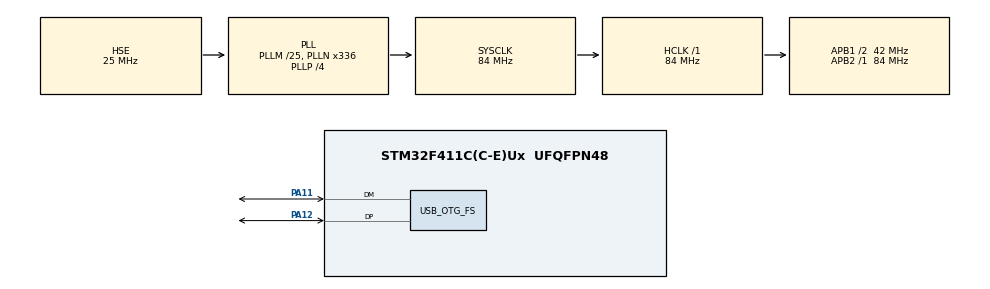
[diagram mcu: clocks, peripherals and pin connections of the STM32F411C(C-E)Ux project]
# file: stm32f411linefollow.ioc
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Mcu.Family=STM32F4
Mcu.Name=STM32F411C(C-E)Ux
Mcu.Package=UFQFPN48
NVIC.PriorityGroup=NVIC_PRIORITYGROUP_4
PA11.Mode=Device_Only
PA11.Signal=USB_OTG_FS_DM
PA12.Mode=Device_Only
PA12.Signal=USB_OTG_FS_DP
PH0\ -\ OSC_IN.Mode=HSE-External-Oscillator
PH0\ -\ OSC_IN.Signal=RCC_OSC_IN
PH1\ -\ OSC_OUT.Mode=HSE-External-Oscillator
PH1\ -\ OSC_OUT.Signal=RCC_OSC_OUT
ProjectManager.HeapSize=0x200
ProjectManager.StackSize=0x400
ProjectManager.TargetToolchain=STM32CubeIDE
RCC.48MHZClocksFreq_Value=48000000
RCC.AHBFreq_Value=84000000
RCC.APB1CLKDivider=RCC_HCLK_DIV2
RCC.APB1Freq_Value=42000000
RCC.APB1TimFreq_Value=84000000
RCC.APB2Freq_Value=84000000
RCC.APB2TimFreq_Value=84000000
RCC.CortexFreq_Value=84000000
RCC.HCLKFreq_Value=84000000
RCC.HSE_VALUE=25000000
RCC.HSI_VALUE=16000000
RCC.LSE_VALUE=32768
RCC.PLLM=25
RCC.PLLN=336
RCC.PLLP=RCC_PLLP_DIV4
RCC.PLLQ=7
RCC.SYSCLKFreq_VALUE=84000000
RCC.SYSCLKSource=RCC_SYSCLKSOURCE_PLLCLK
RCC.VCOOutputFreq_Value=336000000
USB_OTG_FS.VirtualMode=Device_Only
board=custom

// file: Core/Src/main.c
/* USER CODE BEGIN Header */
/**
  ******************************************************************************
  * @file           : main.c
  * @brief          : Main program body
  ******************************************************************************
  * @attention
  *
  * Copyright (c) 2026 STMicroelectronics.
  * All rights reserved.
  *
  * This software is licensed under terms that can be found in the LICENSE file
  * in the root directory of this software component.
  * If no LICENSE file comes with this software, it is provided AS-IS.
  *
  ******************************************************************************
  */
/* USER CODE END Header */
#include "main.h"

/* USER CODE BEGIN Includes */
#include <stdlib.h>
#include <stdint.h>
#include "sensorup.h"
#include "motordrive.h"
#include "config.h"
#include "usb_cdc.h"
/* USER CODE END Includes */

/* USER CODE BEGIN PTD */

float Kp = 0.1f;
float Ki = 0.0f;
float Kd = 0.2f;

int flag = 0;

float error = 0.0f;
float prev_error = 0.0f;
float integral = 0.0f;

int16_t base_speed = 500;
int16_t max_speed  = 1049;      /* = TIM4 ARR (PSC=3, ARR=1049 -> 20 kHz at 84 MHz) */
/* USER CODE END PTD */

/* USER CODE BEGIN PD */
#define DEBUG_PRINT_PERIOD_MS   50U
#define BTN_DEBOUNCE_MS  20U
/* USER CODE END PD */

/* USER CODE BEGIN PM */

/* Returns 1 exactly once per press (on the debounced falling edge of PA0) */

/* USER CODE END PM */

PCD_HandleTypeDef hpcd_USB_OTG_FS;

void SystemClock_Config(void);
static void MX_GPIO_Init(void);
static void MX_USB_OTG_FS_PCD_Init(void);
/* USER CODE BEGIN PFP */
float calculate_error(void)
{
    int32_t weighted_sum = 0;
    int32_t active_count = 0;

    const int16_t weights[8] = {
        -3500, -2500, -1500, -500,
          500,  1500,  2500, 3500
    };

    for (int i = 0; i < 8; i++)
    {
        if (senval[i])
        {
            weighted_sum += weights[i];
            active_count++;
        }
    }

    if (active_count == 0)
    {
        return prev_error;  // Line lost: retain last direction
    }

    return (float)weighted_sum / (float)active_count;
}

float PID_Update(void)
{
    error = calculate_error();

    integral += error;

    float derivative = error - prev_error;

    float output = (Kp * error)
                 + (Ki * integral)
                 + (Kd * derivative);

    prev_error = error;

    return output;
}

void line_follow(void)
{
    float correction = PID_Update();

    int32_t left_speed  = base_speed + (int32_t)correction;
    int32_t right_speed = base_speed - (int32_t)correction;

    if (left_speed > max_speed) left_speed = max_speed;
    if (left_speed < 0)         left_speed = 0;

    if (right_speed > max_speed) right_speed = max_speed;
    if (right_speed < 0)         right_speed = 0;

    LF_SetMotorSpeed((uint16_t)right_speed, (uint16_t)left_speed);
}

/* ---- USB debug output ---------------------------------------------------- */
static uint8_t int_to_str(int32_t v, char *out)
{
    char tmp[11];
    uint8_t n = 0, t = 0;

    if (v < 0) { out[n++] = '-'; v = -v; }
    if (v == 0) tmp[t++] = '0';
    while (v > 0) { tmp[t++] = (char)('0' + (v % 10)); v /= 10; }
    while (t) out[n++] = tmp[--t];
    return n;
}

/* Prints one line like:  S:00011000 E:-500 L:650 R:350
 *   S = sensor bits S1..S8 (left to right, 1 = senval[i] true)
 *   E = error from calculate_error()
 *   L / R = TIM4 CCR3 / CCR4 (the PWM duty actually applied) */
static void usb_debug_print(void)
{
    char line[48];
    uint8_t n = 0;

    line[n++] = 'S'; line[n++] = ':';
    for (int i = 0; i < 8; i++) line[n++] = senval[i] ? '1' : '0';

    line[n++] = ' '; line[n++] = 'E'; line[n++] = ':';
    n += int_to_str((int32_t)error, &line[n]);

    line[n++] = ' '; line[n++] = 'L'; line[n++] = ':';
    n += int_to_str((int32_t)TIM4->CCR3, &line[n]);

    line[n++] = ' '; line[n++] = 'R'; line[n++] = ':';
    n += int_to_str((int32_t)TIM4->CCR4, &line[n]);

    line[n++] = '\r'; line[n++] = '\n';

    cdc_write((const uint8_t *)line, n);    /* non-blocking, never stalls the PID loop */
}

/* USER CODE END PFP */
static uint8_t button_pressed(void)
{
    static uint8_t  stable   = 1U;   /* debounced level, 1 = released (pull-up) */
    static uint8_t  last_raw = 1U;
    static uint32_t t_change = 0U;

    uint8_t  raw = (GPIOA->IDR & (1U << 0U)) ? 1U : 0U;
    uint32_t now = HAL_GetTick();

    if (raw != last_raw)             /* input moved: restart the timer */
    {
        last_raw = raw;
        t_change = now;
    }
    else if ((raw != stable) && ((now - t_change) >= BTN_DEBOUNCE_MS))
    {
        stable = raw;                /* held steady long enough: accept it */
        if (stable == 0U) return 1U; /* pressed */
    }
    return 0U;
}
/* USER CODE BEGIN 0 */
void GO(void)
{

	if(senval[7] == 1 ){
		LF_SetMotorSpeed(0,600);

	}
	if(senval[0] == 1 ){
			LF_SetMotorSpeed(600,0);

		}
	else
	{
    line_follow();
	}
	}
/* USER CODE END 0 */

int main(void)
{

  /* MCU Configuration--------------------------------------------------------*/

  /* Reset of all peripherals, Initializes the Flash interface and the Systick. */
  HAL_Init();

  /* Configure the system clock */
  SystemClock_Config();

  /* Initialize all configured peripherals */
  MX_GPIO_Init();
  MX_USB_OTG_FS_PCD_Init();
  /* USER CODE BEGIN 2 */

  initconfig();
  LF_SetMotorDirection(1U, 1U);
  cdc_init();                       /* start USB virtual COM port */

  /* USER CODE END 2 */

  /* Infinite loop */
  /* USER CODE BEGIN WHILE */
  uint32_t t_last = 0;
  while (1)
  {
    /* USER CODE END WHILE */

    /* USER CODE BEGIN 3 */

    senup();

    // Optional start button (PA0), uncomment to hold the robot until pressed:
    if (button_pressed()) flag = !flag;   /* press to start, press again to stop */
    if (flag == 1) GO();

    if ((HAL_GetTick() - t_last) >= DEBUG_PRINT_PERIOD_MS)
    {
        t_last = HAL_GetTick();
        usb_debug_print();
    }
  }
  /* USER CODE END 3 */
}

void SystemClock_Config(void)
{
  RCC_OscInitTypeDef RCC_OscInitStruct = {0};
  RCC_ClkInitTypeDef RCC_ClkInitStruct = {0};

  /** Configure the main internal regulator output voltage
  */
  __HAL_RCC_PWR_CLK_ENABLE();
  __HAL_PWR_VOLTAGESCALING_CONFIG(PWR_REGULATOR_VOLTAGE_SCALE2);

  /** Initializes the RCC Oscillators according to the specified parameters
  * in the RCC_OscInitTypeDef structure.
  */
  RCC_OscInitStruct.OscillatorType = RCC_OSCILLATORTYPE_HSE;
  RCC_OscInitStruct.HSEState = RCC_HSE_ON;
  RCC_OscInitStruct.PLL.PLLState = RCC_PLL_ON;
  RCC_OscInitStruct.PLL.PLLSource = RCC_PLLSOURCE_HSE;
  RCC_OscInitStruct.PLL.PLLM = 25;
  RCC_OscInitStruct.PLL.PLLN = 336;
  RCC_OscInitStruct.PLL.PLLP = RCC_PLLP_DIV4;
  RCC_OscInitStruct.PLL.PLLQ = 7;
  if (HAL_RCC_OscConfig(&RCC_OscInitStruct) != HAL_OK)
  {
    Error_Handler();
  }

  /** Initializes the CPU, AHB and APB buses clocks
  */
  RCC_ClkInitStruct.ClockType = RCC_CLOCKTYPE_HCLK|RCC_CLOCKTYPE_SYSCLK
                              |RCC_CLOCKTYPE_PCLK1|RCC_CLOCKTYPE_PCLK2;
  RCC_ClkInitStruct.SYSCLKSource = RCC_SYSCLKSOURCE_PLLCLK;
  RCC_ClkInitStruct.AHBCLKDivider = RCC_SYSCLK_DIV1;
  RCC_ClkInitStruct.APB1CLKDivider = RCC_HCLK_DIV2;
  RCC_ClkInitStruct.APB2CLKDivider = RCC_HCLK_DIV1;

  if (HAL_RCC_ClockConfig(&RCC_ClkInitStruct, FLASH_LATENCY_2) != HAL_OK)
  {
    Error_Handler();
  }
}

static void MX_USB_OTG_FS_PCD_Init(void)
{

  hpcd_USB_OTG_FS.Instance = USB_OTG_FS;
  hpcd_USB_OTG_FS.Init.dev_endpoints = 4;
  hpcd_USB_OTG_FS.Init.speed = PCD_SPEED_FULL;
  hpcd_USB_OTG_FS.Init.dma_enable = DISABLE;
  hpcd_USB_OTG_FS.Init.phy_itface = PCD_PHY_EMBEDDED;
  hpcd_USB_OTG_FS.Init.Sof_enable = DISABLE;
  hpcd_USB_OTG_FS.Init.low_power_enable = DISABLE;
  hpcd_USB_OTG_FS.Init.lpm_enable = DISABLE;
  hpcd_USB_OTG_FS.Init.vbus_sensing_enable = DISABLE;
  hpcd_USB_OTG_FS.Init.use_dedicated_ep1 = DISABLE;
  if (HAL_PCD_Init(&hpcd_USB_OTG_FS) != HAL_OK)
  {
    Error_Handler();
  }

}

static void MX_GPIO_Init(void)
{

  /* GPIO Ports Clock Enable */
  __HAL_RCC_GPIOH_CLK_ENABLE();
  __HAL_RCC_GPIOA_CLK_ENABLE();

}

void Error_Handler(void)
{
  __disable_irq();
  while (1)
  {
  }
}
